# G32R501 register map
Vendor: Geehy Semiconductor Co., Ltd.; Series: G32R5; File version: 1.0
CPU: CM55 r0p1, little endian, MPU, FPU, double-precision FPU, DSP, VTOR, 4 interrupt priority bits
Registers are 32-bit, read-write, reset 0x0 unless marked. A register's access mark holds for its fields unless they carry their own. Offsets are from the block's base; [hi:lo] are bit positions.

## NVMC
Base 0x50010000
0x00 FRDCNTL — Flaash read control register
  [15:8] RWAIT — Read waitstate
0x3C FBAC — Flash Bank Access Control Register
  [15:8] BAGP — Bank Counter reload value Set
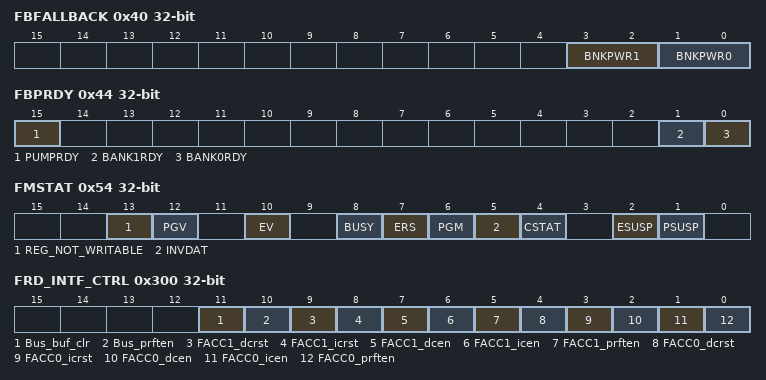
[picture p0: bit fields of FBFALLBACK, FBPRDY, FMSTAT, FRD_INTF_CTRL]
0x40 FBFALLBACK — Flash Bank Fallback Power Register
  [3:2] BNKPWR1 — Bank 1 Fall Back power mode select
  [1:0] BNKPWR0 — Bank 0 Fall Back power mode select
0x44 FBPRDY ro — Flash Bank Pump Ready Register
  [15] PUMPRDY — Pump Ready Flag
  [1] BANK1RDY — Bank 1 Ready Flag
  [0] BANK0RDY — Bank 0 Ready Flag
0x54 FMSTAT ro — Flash Module Status Register
  [13] REG_NOT_WRITABLE — Disable Write Register
  [12] PGV — program Failed Flag
  [10] EV — erase Failed Flag
  [8] BUSY — Busy Flag
  [7] ERS — Executive Erase Flag
  [6] PGM — Executive program Flag
  [5] INVDAT — Invalid Data Flag
  [4] CSTAT — Command Error Flag
  [2] ESUSP — Flash receives and processed a erase pend Flag
  [1] PSUSP — Flash receives and processed a program pend Flag
0x300 FRD_INTF_CTRL — Flash Read Interface Control Register
  [11] Bus_buf_clr — busmatrix interface buffer Clear
  [10] Bus_prften — busmatrix interface Prefetch enable
  [9] FACC1_dcrst — CPU1 ART accelerator Data cache clear
  [8] FACC1_icrst — CPU1 ART accelerator Instructions cache clear
  [7] FACC1_dcen — CPU1 ART accelerator Data cache enable
  [6] FACC1_icen — CPU1 ART accelerator Instructions cache enable
  [5] FACC1_prften — CPU1 ART accelerator Prefetch enable
  [4] FACC0_dcrst — CPU0 ART accelerator Data cache clear
  [3] FACC0_icrst — CPU0 ART accelerator Instructions cache clear
  [2] FACC0_dcen — CPU0 ART accelerator Data cache enable
  [1] FACC0_icen — ART accelerator Instructions cache enable
  [0] FACC0_prften — CPU0 ART accelerator Prefetch enable
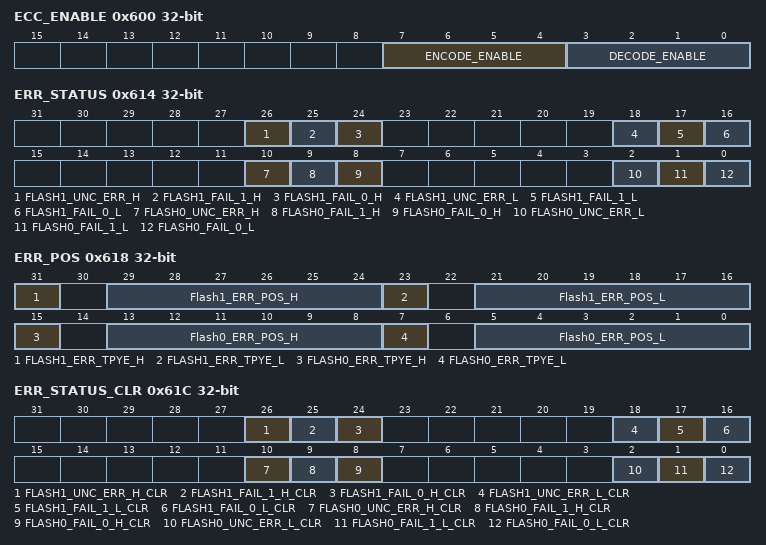
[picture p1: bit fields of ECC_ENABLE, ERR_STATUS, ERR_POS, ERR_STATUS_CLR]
0x600 ECC_ENABLE
  [7:4] ENCODE_ENABLE — ECC encode enable
  [3:0] DECODE_ENABLE — ECC decode enable
0x604 SINGLE_ERR_ADDR_LOW_0 — FLASH Bank0 single error address low
  [31:0] ERR_ADDR_L_0
0x608 SINGLE_ERR_ADDR_HIGH_0 — FLASH Bank0 single error address high
  [31:0] ERR_ADDR_H_0
0x60C UNC_ERR_ADDR_LOW_0 — FLASH Bank0 uncorrectable error address low
  [31:0] UNC_ERR_ADDR_L_0
0x610 UNC_ERR_ADDR_HIGH_0 — FLASH Bank0 uncorrectable error address high
  [31:0] UNC_ERR_ADDR_H_0
0x614 ERR_STATUS ro — Error status
  [26] FLASH1_UNC_ERR_H — FLASH1 Uncorrectable Error High Flag
  [25] FLASH1_FAIL_1_H — FLASH1 Fail on 1 Single Error High Flag
  [24] FLASH1_FAIL_0_H — FLASH1 Fail on 0 Single Error High Flag
  [18] FLASH1_UNC_ERR_L — FLASH1 Uncorrectable Error Low Flag
  [17] FLASH1_FAIL_1_L — FLASH1 Fail on 1 Single Error Low Flag
  [16] FLASH1_FAIL_0_L — FLASH1 Fail on 0 Single Error Low Flag
  [10] FLASH0_UNC_ERR_H — FLASH0 Uncorrectable Error High Flag
  [9] FLASH0_FAIL_1_H — FLASH0 Fail on 1 Single Error High Flag
  [8] FLASH0_FAIL_0_H — FLASH0 Fail on 0 Single Error High Flag
  [2] FLASH0_UNC_ERR_L — FLASH0 Uncorrectable Error Low Flag
  [1] FLASH0_FAIL_1_L — FLASH0 Fail on 1 Single Error Low Flag
  [0] FLASH0_FAIL_0_L — FLASH0 Fail on 0 Single Error Low Flag
0x618 ERR_POS — Error position
  [31] FLASH1_ERR_TPYE_H — FLASH1 Error type High
  [29:24] Flash1_ERR_POS_H — FLASH1 Error position High
  [23] FLASH1_ERR_TPYE_L — FLASH1 Error type Low
  [21:16] Flash1_ERR_POS_L — FLASH1 Error position Low
  [15] FLASH0_ERR_TPYE_H — FLASH0 Error type High
  [13:8] Flash0_ERR_POS_H — FLASH0 Error position High
  [7] FLASH0_ERR_TPYE_L — FLASH0 Error type Low
  [5:0] Flash0_ERR_POS_L — FLASH0 Error position Low
0x61C ERR_STATUS_CLR — Error status clear
  [26] FLASH1_UNC_ERR_H_CLR — FLASH1 Uncorrectable Error High Flag clear
  [25] FLASH1_FAIL_1_H_CLR — FLASH1 Fail on 1 Single Error High Flag clear
  [24] FLASH1_FAIL_0_H_CLR — FLASH1 Fail on 0 Single Error High Flag clear
  [18] FLASH1_UNC_ERR_L_CLR — FLASH1 Uncorrectable Error Low Flag clear
  [17] FLASH1_FAIL_1_L_CLR — FLASH1 Fail on 1 Single Error Low Flag clear
  [16] FLASH1_FAIL_0_L_CLR — FLASH1 Fail on 0 Single Error Low Flag clear
  [10] FLASH0_UNC_ERR_H_CLR — FLASH0 Uncorrectable Error High Flag clear
  [9] FLASH0_FAIL_1_H_CLR — FLASH0 Fail on 1 Single Error High Flag clear
  [8] FLASH0_FAIL_0_H_CLR — FLASH0 Fail on 0 Single Error High Flag clear
  [2] FLASH0_UNC_ERR_L_CLR — FLASH0 Uncorrectable Error Low Flag clear
  [1] FLASH0_FAIL_1_L_CLR — FLASH0 Fail on 1 Single Error Low Flag clear
  [0] FLASH0_FAIL_0_L_CLR — FLASH0 Fail on 0 Single Error Low Flag clear
0x620 ERR_CNT — Error counter
  [15:0] ERR_CNT — Single bit error count
0x624 ERR_THRESHOLD — Error threshold
  [15:0] ERR_THRESHOLD — Single bit error threshold
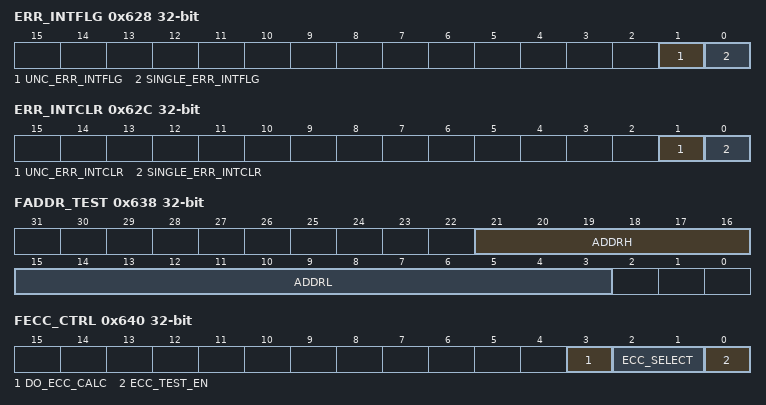
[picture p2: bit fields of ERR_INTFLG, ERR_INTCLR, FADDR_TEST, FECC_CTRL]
0x628 ERR_INTFLG ro — Error interrupt flag
  [1] UNC_ERR_INTFLG — Uncorrectable error interrupt flag
  [0] SINGLE_ERR_INTFLG — Single bit error interrupt flag
0x62C ERR_INTCLR — Error interrupt clear
  [1] UNC_ERR_INTCLR — Uncorrectable error interrupt flag clear
  [0] SINGLE_ERR_INTCLR — Single bit error interrupt flag clear
0x630 FDATAH_TEST — Data high test
  [31:0] FDATAH — Selected Data High
0x634 FDATAL_TEST — Data low test
  [31:0] FDATAL — Selected Data Low
0x638 FADDR_TEST — ECC test address
  [21:16] ADDRH — Selected data Address high
  [15:3] ADDRL — Selected data Address low
0x63C FECC_TEST — ECC test ECC
  [7:0] ECC — Selected data ECC
0x640 FECC_CTRL — ECC control
  [3] DO_ECC_CALC — Enable ECC calculation
  [2:1] ECC_SELECT — ECC block select
  [0] ECC_TEST_EN — ECC test mode enable
0x644 FOUTH_TEST ro — Test data out high
  [31:0] DATAOUTH — Test data High
0x648 FOUTL_TEST ro — Tess data out low
  [31:0] DATAOUTL — Test data Low
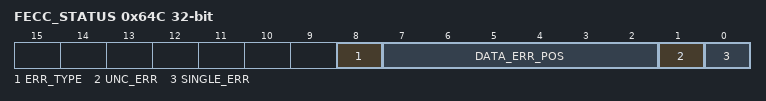
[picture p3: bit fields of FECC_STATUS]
0x64C FECC_STATUS ro — ECC status
  [8] ERR_TYPE — Test mode single bit error type
  [7:2] DATA_ERR_POS — Test mode single bit error position
  [1] UNC_ERR — Test mode Uncorrectable Error Flag
  [0] SINGLE_ERR — Test mode ECC single bit error Flag
0x650 SINGLE_ERR_ADDR_LOW_1 — FLASH Bank1 single error address low
  [31:0] ERR_ADDR_L_1
0x654 SINGLE_ERR_ADDR_HIGH_1 — FLASH Bank1 single error address high
  [31:0] ERR_ADDR_H_1
0x658 UNC_ERR_ADDR_LOW_1 — FLASH Bank1 uncorrectable error address low
  [31:0] UNC_ERR_ADDR_L_1
0x65C UNC_ERR_ADDR_HIGH_1 — FLASH Bank1 uncorrectable error address high
  [31:0] UNC_ERR_ADDR_H_1
